# MK10D5 register map
File version: 1.6
Registers are 8-bit, read-write, reset 0x0 unless marked. A register's access mark holds for its fields unless they carry their own. Offsets are from the block's base; [hi:lo] are bit positions; {n}, {i} and the like mark numbered series.

## PIT — Periodic Interrupt Timer
Base 0x40037000; register names take the prefix PIT_
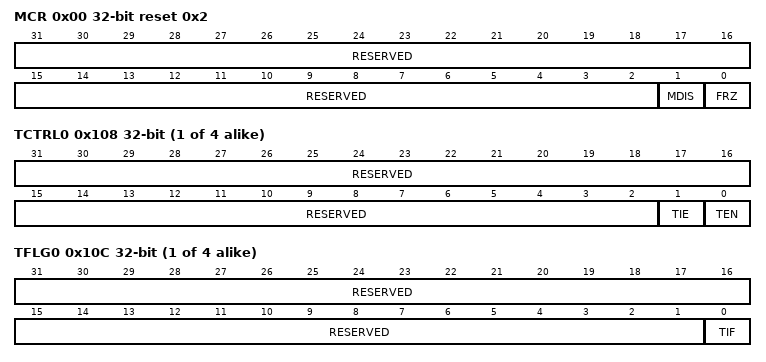
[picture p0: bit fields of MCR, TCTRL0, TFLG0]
0x00 MCR 32-bit access per field reset 0x2 — PIT Module Control Register
  [31:2] RESERVED ro
  [1] MDIS rw — Module Disable
    0=Clock for PIT Timers is enabled; 1=Clock for PIT Timers is disabled
  [0] FRZ rw — Freeze
    0=Timers continue to run in debug mode; 1=Timers are stopped in debug mode
{0x100+0x10*i} LDVAL{i} (i=0..3) 32-bit — Timer Load Value Register
  [31:0] TSV — Timer Start Value Bits
{0x104+0x10*i} CVAL{i} (i=0..3) 32-bit ro — Current Timer Value Register
  [31:0] TVL — Current Timer Value
{0x108+0x10*i} TCTRL{i} (i=0..3) 32-bit access per field — Timer Control Register
  [31:2] RESERVED ro
  [1] TIE rw — Timer Interrupt Enable Bit.
    0=Interrupt requests from Timer n are disabled; 1=Interrupt will be requested whenever TIF is set
  [0] TEN rw — Timer Enable Bit.
    0=Timer n is disabled; 1=Timer n is active
{0x10C+0x10*i} TFLG{i} (i=0..3) 32-bit access per field — Timer Flag Register
  [31:1] RESERVED ro
  [0] TIF rw — Timer Interrupt Flag.
    0=Time-out has not yet occurred; 1=Time-out has occurred

## RFVBAT — VBAT register file
Base 0x4003E000; register names take the prefix RFVBAT_
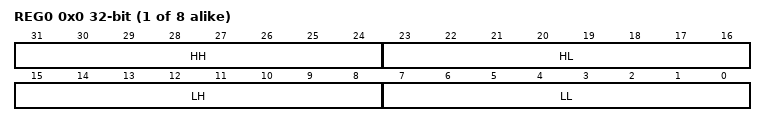
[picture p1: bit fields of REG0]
{0x0+4i} REG{i} (i=0..7) 32-bit — VBAT register file register
  [31:24] HH, [23:16] HL, [15:8] LH, [7:0] LL

## LPTMR0 — Low Power Timer
Base 0x40040000; register names take the prefix LPTMR0_
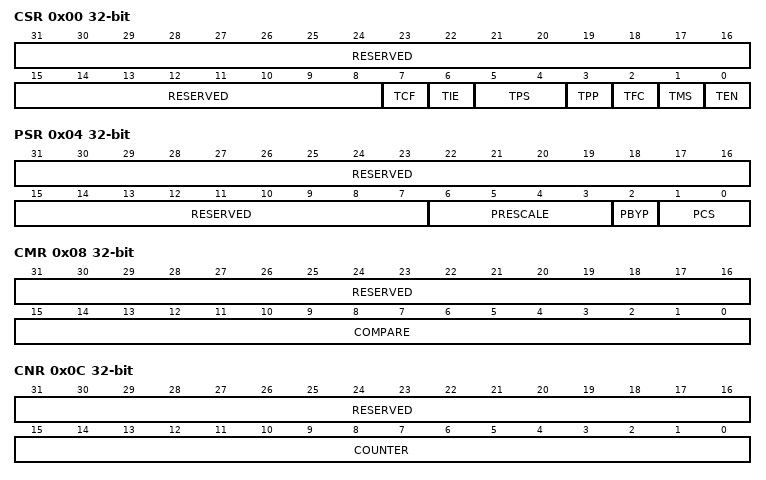
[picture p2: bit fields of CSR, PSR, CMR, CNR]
0x00 CSR 32-bit access per field — Low Power Timer Control Status Register
  [31:8] RESERVED ro
  [7] TCF rw — Timer Compare Flag
    0=LPTMR Counter Register has not equaled the LPTMR Compare Register and incremented; 1=LPTMR Counter Register has equaled the LPTMR Compare Register and incremented
  [6] TIE rw — Timer Interrupt Enable
    0=Timer Interrupt Disabled; 1=Timer Interrupt Enabled
  [5:4] TPS rw — Timer Pin Select
    {v}=Pulse counter input {v} is selected (v=0..3)
  [3] TPP rw — Timer Pin Polarity
    0=Pulse Counter input source is active high, and LPTMR Counter Register will increment on the rising edge; 1=Pulse Counter input source is active low, and LPTMR Counter Register will increment on the falling edge
  [2] TFC rw — Timer Free Running Counter
    0=LPTMR Counter Register is reset whenever the Timer Compare Flag is set; 1=LPTMR Counter Register is reset on overflow
  [1] TMS rw — Timer Mode Select
    0=Time Counter mode; 1=Pulse Counter mode
  [0] TEN rw — Timer Enable
    0=LPTMR is disabled and internal logic is reset; 1=LPTMR is enabled
0x04 PSR 32-bit access per field — Low Power Timer Prescale Register
  [31:7] RESERVED ro
  [6:3] PRESCALE rw — Prescale Value
    0=Prescaler divides the prescaler clock by 2; Glitch Filter does not support this configuration; 1=Prescaler divides the prescaler clock by 4; Glitch Filter recognizes change on input pin after 2 rising clock edges; 2=Prescaler divides the prescaler clock by 8; Glitch Filter recognizes change on input pin after 4 rising clock edges; 3=Prescaler divides the prescaler clock by 16; Glitch Filter recognizes change on input pin after 8 rising clock edges; 4=Prescaler divides the prescaler clock by 32; Glitch Filter recognizes change on input pin after 16 rising clock edges; 5=Prescaler divides the prescaler clock by 64; Glitch Filter recognizes change on input pin after 32 rising clock edges; 6=Prescaler divides the prescaler clock by 128; Glitch Filter recognizes change on input pin after 64 rising clock edges; 7=Prescaler divides the prescaler clock by 256; Glitch Filter recognizes change on input pin after 128 rising clock edges; 8=Prescaler divides the prescaler clock by 512; Glitch Filter recognizes change on input pin after 256 rising clock edges; 9=Prescaler divides the prescaler clock by 1024; Glitch Filter recognizes change on input pin after 512 rising clock edges; 10=Prescaler divides the prescaler clock by 2048; Glitch Filter recognizes change on input pin after 1024 rising clock edges; 11=Prescaler divides the prescaler clock by 4096; Glitch Filter recognizes change on input pin after 2048 rising clock edges; 12=Prescaler divides the prescaler clock by 8192; Glitch Filter recognizes change on input pin after 4096 rising clock edges; 13=Prescaler divides the prescaler clock by 16384; Glitch Filter recognizes change on input pin after 8192 rising clock edges; 14=Prescaler divides the prescaler clock by 32768; Glitch Filter recognizes change on input pin after 16384 rising clock edges; 15=Prescaler divides the prescaler clock by 65536; Glitch Filter recognizes change on input pin after 32768 rising clock edges
  [2] PBYP rw — Prescaler Bypass
    0=Prescaler/Glitch Filter is enabled; 1=Prescaler/Glitch Filter is bypassed
  [1:0] PCS rw — Prescaler Clock Select
    {v}=Prescaler/glitch filter clock {v} selected (v=0..3)
0x08 CMR 32-bit access per field — Low Power Timer Compare Register
  [31:16] RESERVED ro
  [15:0] COMPARE rw — Compare Value
0x0C CNR 32-bit ro — Low Power Timer Counter Register
  [31:16] RESERVED
  [15:0] COUNTER — Counter Value
